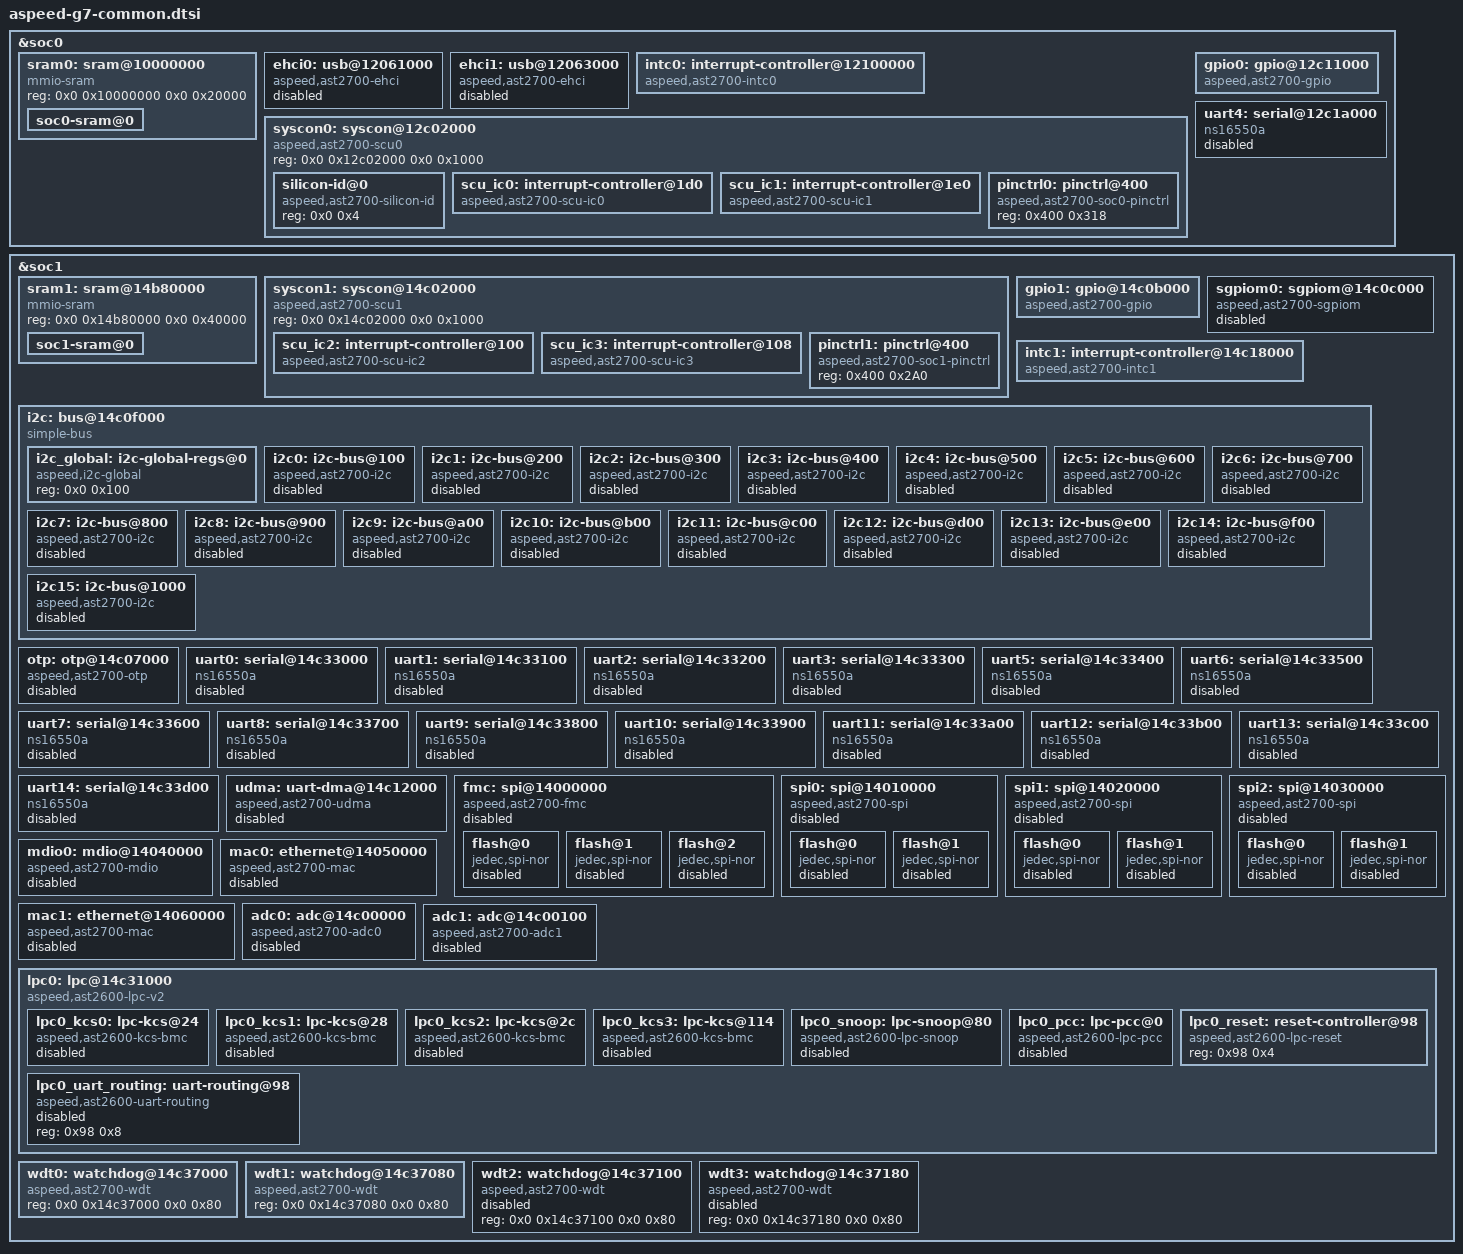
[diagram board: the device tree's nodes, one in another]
// SPDX-License-Identifier: GPL-2.0-only OR MIT
/*
 * Device Tree Source for AST27xx SoC Family Main Domain peripherals
 *
 * Copyright (C) 2026 ASPEED Technology Inc.
 */

#include <dt-bindings/clock/aspeed,ast2700-scu.h>
#include <dt-bindings/reset/aspeed,ast2700-scu.h>
#include <dt-bindings/interrupt-controller/aspeed-scu-ic.h>

&soc0 {
	sram0: sram@10000000 {
		compatible = "mmio-sram";
		reg = <0x0 0x10000000 0x0 0x20000>;
		ranges = <0x0 0x0 0x10000000 0x20000>;
		#address-cells = <1>;
		#size-cells = <1>;

		soc0-sram@0 {
			reg = <0x0 0x20000>;
			export;
		};
	};

	ehci0: usb@12061000 {
		compatible = "aspeed,ast2700-ehci", "generic-ehci";
		reg = <0x0 0x12061000 0x0 0x100>;
		interrupts = <GIC_SPI 33 IRQ_TYPE_LEVEL_HIGH>;
		clocks = <&syscon0 SCU0_CLK_GATE_PORTAUSB2CLK>;
		resets = <&syscon0 SCU0_RESET_PORTA_VHUB_EHCI>;
		pinctrl-names = "default";
		pinctrl-0 = <&pinctrl_usb2ah_default>;
		status = "disabled";
	};

	ehci1: usb@12063000 {
		compatible = "aspeed,ast2700-ehci", "generic-ehci";
		reg = <0x0 0x12063000 0x0 0x100>;
		interrupts = <GIC_SPI 37 IRQ_TYPE_LEVEL_HIGH>;
		clocks = <&syscon0 SCU0_CLK_GATE_PORTBUSB2CLK>;
		resets = <&syscon0 SCU0_RESET_PORTB_VHUB_EHCI>;
		pinctrl-names = "default";
		pinctrl-0 = <&pinctrl_usb2bh_default>;
		status = "disabled";
	};

	intc0: interrupt-controller@12100000 {
		compatible = "aspeed,ast2700-intc0";
		reg = <0x0 0x12100000 0x0 0x3c00>;
		interrupt-controller;
		interrupt-parent = <&gic>;
		#interrupt-cells = <1>;
		aspeed,interrupt-ranges =
			<0 128 &gic GIC_SPI 0 IRQ_TYPE_LEVEL_HIGH>, /* linear range 1 to 1*/
			<144 8 &gic GIC_SPI 144 IRQ_TYPE_LEVEL_HIGH>, /* sw int SSP */
			<152 8 &gic GIC_SPI 152 IRQ_TYPE_LEVEL_HIGH>, /* sw int TSP */
			<192 10 &gic GIC_SPI 192 IRQ_TYPE_LEVEL_HIGH>, /* M0-M9 intm */
			<208 10 &gic GIC_SPI 208 IRQ_TYPE_LEVEL_HIGH>, /* M30-M39 intm */
			<224 10 &gic GIC_SPI 224 IRQ_TYPE_LEVEL_HIGH>, /* M40-M49 intm */
			<256 128 &ssp_nvic 0 0 >, /* linear to SSP */
			<384 10 &ssp_nvic 160 0 >, /* cascaded to SSP via M10-M19 */
			<400 8 &ssp_nvic 144 0 >, /* sw int PSP */
			<408 8 &ssp_nvic 152 0 >, /* sw int TSP */
			<426 128 &tsp_nvic 0 0 >, /* linear to TSP */
			<554 10 &tsp_nvic 160 0 >, /* cascaded to TSP via M20-M29 */
			<570 8 &tsp_nvic 144 0 >, /* sw int PSP */
			<578 8 &tsp_nvic 152 0 >; /* sw int TSP */
	};

	syscon0: syscon@12c02000 {
		compatible = "aspeed,ast2700-scu0", "syscon", "simple-mfd";
		reg = <0x0 0x12c02000 0x0 0x1000>;
		ranges = <0x0 0x0 0x12c02000 0x1000>;
		#address-cells = <1>;
		#size-cells = <1>;
		#clock-cells = <1>;
		#reset-cells = <1>;

		silicon-id@0 {
			compatible = "aspeed,ast2700-silicon-id", "aspeed,silicon-id";
			reg = <0x0 0x4>;
		};

		scu_ic0: interrupt-controller@1d0 {
			compatible = "aspeed,ast2700-scu-ic0";
			reg = <0x1d0 0xc>;
			interrupts-extended = <&intc0 97>;
			#interrupt-cells = <1>;
			interrupt-controller;
		};

		scu_ic1: interrupt-controller@1e0 {
			compatible = "aspeed,ast2700-scu-ic1";
			reg = <0x1e0 0xc>;
			interrupts-extended = <&intc0 98>;
			#interrupt-cells = <1>;
			interrupt-controller;
		};

		pinctrl0: pinctrl@400 {
			compatible = "aspeed,ast2700-soc0-pinctrl";
			reg = <0x400 0x318>;
		};
	};

	gpio0: gpio@12c11000 {
		#gpio-cells = <2>;
		gpio-controller;
		compatible = "aspeed,ast2700-gpio";
		reg = <0x0 0x12c11000 0x0 0x1000>;
		interrupts-extended = <&intc0 11>;
		gpio-ranges = <&pinctrl0 0 0 12>;
		ngpios = <12>;
		clocks = <&syscon0 SCU0_CLK_APB>;
		interrupt-controller;
		#interrupt-cells = <2>;
	};

	uart4: serial@12c1a000 {
		compatible = "ns16550a";
		reg = <0x0 0x12c1a000 0x0 0x1000>;
		reg-shift = <2>;
		reg-io-width = <4>;
		clocks = <&syscon0 SCU0_CLK_GATE_UART4CLK>;
		interrupts-extended = <&intc0 8>;
		no-loopback-test;
		status = "disabled";
	};
};

&soc1 {
	sram1: sram@14b80000 {
		compatible = "mmio-sram";
		reg = <0x0 0x14b80000 0x0 0x40000>;
		ranges = <0x0 0x0 0x14b80000 0x40000>;
		#address-cells = <1>;
		#size-cells = <1>;

		soc1-sram@0 {
			reg = <0x0 0x40000>;
			export;
		};
	};

	syscon1: syscon@14c02000 {
		compatible = "aspeed,ast2700-scu1", "syscon", "simple-mfd";
		reg = <0x0 0x14c02000 0x0 0x1000>;
		ranges = <0x0 0x0 0x14c02000 0x1000>;
		#address-cells = <1>;
		#size-cells = <1>;
		#clock-cells = <1>;
		#reset-cells = <1>;

		scu_ic2: interrupt-controller@100 {
			compatible = "aspeed,ast2700-scu-ic2";
			reg = <0x100 0x8>;
			interrupts-extended = <&intc1 160>;
			#interrupt-cells = <1>;
			interrupt-controller;
		};

		scu_ic3: interrupt-controller@108 {
			compatible = "aspeed,ast2700-scu-ic3";
			reg = <0x108 0x8>;
			interrupts-extended = <&intc1 186>;
			#interrupt-cells = <1>;
			interrupt-controller;
		};

		pinctrl1: pinctrl@400 {
			compatible = "aspeed,ast2700-soc1-pinctrl";
			reg = <0x400 0x2A0>;
		};
	};

	gpio1: gpio@14c0b000 {
		#gpio-cells = <2>;
		gpio-controller;
		compatible = "aspeed,ast2700-gpio";
		reg = <0x0 0x14c0b000 0x0 0x1000>;
		interrupts-extended = <&intc1 82>;
		gpio-ranges = <&pinctrl1 0 0 216>;
		ngpios = <216>;
		clocks = <&syscon1 SCU1_CLK_AHB>;
		interrupt-controller;
		#interrupt-cells = <2>;
	};

	sgpiom0: sgpiom@14c0c000 {
		#gpio-cells = <2>;
		gpio-controller;
		compatible = "aspeed,ast2700-sgpiom";
		reg = <0x0 0x14c0c000 0x0 0x100>;
		interrupts-extended = <&intc1 85>;
		clocks = <&syscon1 SCU1_CLK_APB>;
		interrupt-controller;
		#interrupt-cells = <2>;
		ngpios = <256>;
		bus-frequency = <12000000>;
		pinctrl-names = "default";
		pinctrl-0 = <&pinctrl_sgpm0_default>;
		status = "disabled";
	};

	intc1: interrupt-controller@14c18000 {
		compatible = "aspeed,ast2700-intc1";
		reg = <0 0x14c18000 0 0x400>;
		interrupt-controller;
		interrupt-parent = <&intc0>;
		#interrupt-cells = <1>;
		aspeed,interrupt-ranges =
			<0 6 &intc0 480>,   /* M0  ~ M5  */
			<10 6 &intc0 490>,   /* M10 ~ M15  */
			<20 6 &intc0 500>,   /* M20 ~ M15  */
			<30 6 &intc0 510>,   /* M30 ~ M15  */
			<40 6 &intc0 520>,   /* M40 ~ M15  */
			<50 1 &bootmcu_intc 0>; /* only 1 pin to BootMCU */
	};

	i2c: bus@14c0f000 {
		compatible = "simple-bus";
		#address-cells = <1>;
		#size-cells = <1>;
		ranges = <0x0 0x0 0x14c0f000 0x1100>;
	};

	otp: otp@14c07000 {
		compatible = "aspeed,ast2700-otp";
		reg = <0 0x14c07000 0 0x1000>;
		interrupts-extended = <&intc1 168>;
		aspeed,scu0 = <&syscon0>;
		aspeed,scu1 = <&syscon1>;
		status = "disabled";
	};

	uart0: serial@14c33000 {
		compatible = "ns16550a";
		reg = <0x0 0x14c33000 0x0 0x100>;
		reg-shift = <2>;
		reg-io-width = <4>;
		clocks = <&syscon1 SCU1_CLK_GATE_UART0CLK>;
		interrupts-extended = <&intc1 135>;
		no-loopback-test;
		status = "disabled";
	};

	uart1: serial@14c33100 {
		compatible = "ns16550a";
		reg = <0x0 0x14c33100 0x0 0x100>;
		reg-shift = <2>;
		reg-io-width = <4>;
		clocks = <&syscon1 SCU1_CLK_GATE_UART1CLK>;
		interrupts-extended = <&intc1 136>;
		no-loopback-test;
		status = "disabled";
	};

	uart2: serial@14c33200 {
		compatible = "ns16550a";
		reg = <0x0 0x14c33200 0x0 0x100>;
		reg-shift = <2>;
		reg-io-width = <4>;
		clocks = <&syscon1 SCU1_CLK_GATE_UART2CLK>;
		interrupts-extended = <&intc1 137>;
		no-loopback-test;
		status = "disabled";
	};

	uart3: serial@14c33300 {
		compatible = "ns16550a";
		reg = <0x0 0x14c33300 0x0 0x100>;
		reg-shift = <2>;
		reg-io-width = <4>;
		clocks = <&syscon1 SCU1_CLK_GATE_UART3CLK>;
		interrupts-extended = <&intc1 138>;
		no-loopback-test;
		status = "disabled";
	};

	uart5: serial@14c33400 {
		compatible = "ns16550a";
		reg = <0x0 0x14c33400 0x0 0x100>;
		reg-shift = <2>;
		reg-io-width = <4>;
		clocks = <&syscon1 SCU1_CLK_GATE_UART5CLK>;
		interrupts-extended = <&intc1 139>;
		no-loopback-test;
		status = "disabled";
	};

	uart6: serial@14c33500 {
		compatible = "ns16550a";
		reg = <0x0 0x14c33500 0x0 0x100>;
		reg-shift = <2>;
		reg-io-width = <4>;
		clocks = <&syscon1 SCU1_CLK_GATE_UART6CLK>;
		interrupts-extended = <&intc1 140>;
		no-loopback-test;
		status = "disabled";
	};

	uart7: serial@14c33600 {
		compatible = "ns16550a";
		reg = <0x0 0x14c33600 0x0 0x100>;
		reg-shift = <2>;
		reg-io-width = <4>;
		clocks = <&syscon1 SCU1_CLK_GATE_UART7CLK>;
		interrupts-extended = <&intc1 141>;
		no-loopback-test;
		status = "disabled";
	};

	uart8: serial@14c33700 {
		compatible = "ns16550a";
		reg = <0x0 0x14c33700 0x0 0x100>;
		reg-shift = <2>;
		reg-io-width = <4>;
		clocks = <&syscon1 SCU1_CLK_GATE_UART8CLK>;
		interrupts-extended = <&intc1 142>;
		no-loopback-test;
		status = "disabled";
	};

	uart9: serial@14c33800 {
		compatible = "ns16550a";
		reg = <0x0 0x14c33800 0x0 0x100>;
		reg-shift = <2>;
		reg-io-width = <4>;
		clocks = <&syscon1 SCU1_CLK_GATE_UART9CLK>;
		interrupts-extended = <&intc1 143>;
		no-loopback-test;
		status = "disabled";
	};

	uart10: serial@14c33900 {
		compatible = "ns16550a";
		reg = <0x0 0x14c33900 0x0 0x100>;
		reg-shift = <2>;
		reg-io-width = <4>;
		clocks = <&syscon1 SCU1_CLK_GATE_UART10CLK>;
		interrupts-extended = <&intc1 144>;
		no-loopback-test;
		status = "disabled";
	};

	uart11: serial@14c33a00 {
		compatible = "ns16550a";
		reg = <0x0 0x14c33a00 0x0 0x100>;
		reg-shift = <2>;
		reg-io-width = <4>;
		clocks = <&syscon1 SCU1_CLK_GATE_UART11CLK>;
		interrupts-extended = <&intc1 145>;
		no-loopback-test;
		status = "disabled";
	};

	uart12: serial@14c33b00 {
		compatible = "ns16550a";
		reg = <0x0 0x14c33b00 0x0 0x100>;
		reg-shift = <2>;
		reg-io-width = <4>;
		clocks = <&syscon1 SCU1_CLK_GATE_UART12CLK>;
		interrupts-extended = <&intc1 146>;
		no-loopback-test;
		status = "disabled";
	};

	uart13: serial@14c33c00 {
		compatible = "ns16550a";
		reg = <0x0 0x14c33c00 0x0 0x100>;
		reg-shift = <2>;
		reg-io-width = <4>;
		clocks = <&syscon1 SCU1_CLK_UART13>;
		interrupts-extended = <&intc1 23>;
		no-loopback-test;
		status = "disabled";
	};

	uart14: serial@14c33d00 {
		compatible = "ns16550a";
		reg = <0x0 0x14c33d00 0x0 0x100>;
		reg-shift = <2>;
		reg-io-width = <4>;
		clocks = <&syscon1 SCU1_CLK_UART14>;
		interrupts-extended = <&intc1 55>;
		no-loopback-test;
		status = "disabled";
	};

	udma: uart-dma@14c12000 {
		compatible = "aspeed,ast2700-udma";
		reg = <0x0 0x14c12000 0x0 0x1000>;
		interrupts-extended = <&intc1 147>;
		dma-channels = <32>;
		#dma-cells = <1>;
		status = "disabled";
	};

	fmc: spi@14000000 {
		reg = <0x0 0x14000000 0x0 0xc4>, <0x1 0x00000000 0x0 0x80000000>;
		#address-cells = <1>;
		#size-cells = <0>;
		compatible = "aspeed,ast2700-fmc";
		clocks = <&syscon1 SCU1_CLK_AHB>;
		interrupts-extended = <&intc1 121>;
		status = "disabled";
		num-cs = <3>;

		flash@0 {
			reg = < 0 >;
			compatible = "jedec,spi-nor";
			spi-max-frequency = <50000000>;
			spi-rx-bus-width = <2>;
			status = "disabled";
		};

		flash@1 {
			reg = < 1 >;
			compatible = "jedec,spi-nor";
			spi-max-frequency = <50000000>;
			spi-rx-bus-width = <2>;
			status = "disabled";
		};

		flash@2 {
			reg = < 2 >;
			compatible = "jedec,spi-nor";
			spi-max-frequency = <50000000>;
			spi-rx-bus-width = <2>;
			status = "disabled";
		};
	};

	spi0: spi@14010000 {
		reg = <0x0 0x14010000 0x0 0xc4>, <0x1 0x80000000 0x0 0x80000000>;
		#address-cells = <1>;
		#size-cells = <0>;
		compatible = "aspeed,ast2700-spi";
		clocks = <&syscon1 SCU1_CLK_AHB>;
		interrupts-extended = <&intc1 122>;
		status = "disabled";
		num-cs = <2>;

		flash@0 {
			reg = < 0 >;
			compatible = "jedec,spi-nor";
			spi-max-frequency = <50000000>;
			spi-rx-bus-width = <2>;
			status = "disabled";
		};

		flash@1 {
			reg = < 1 >;
			compatible = "jedec,spi-nor";
			spi-max-frequency = <50000000>;
			spi-rx-bus-width = <2>;
			status = "disabled";
		};
	};

	spi1: spi@14020000 {
		reg = <0x0 0x14020000 0x0 0xc4>, <0x2 0x00000000 0x0 0x80000000>;
		#address-cells = <1>;
		#size-cells = <0>;
		compatible = "aspeed,ast2700-spi";
		clocks = <&syscon1 SCU1_CLK_AHB>;
		interrupts-extended = <&intc1 123>;
		status = "disabled";
		num-cs = <2>;

		flash@0 {
			reg = < 0 >;
			compatible = "jedec,spi-nor";
			spi-max-frequency = <50000000>;
			spi-rx-bus-width = <2>;
			status = "disabled";
		};

		flash@1 {
			reg = < 1 >;
			compatible = "jedec,spi-nor";
			spi-max-frequency = <50000000>;
			spi-rx-bus-width = <2>;
			status = "disabled";
		};
	};

	spi2: spi@14030000 {
		reg = <0x0 0x14030000 0x0 0x1f0>, <0x2 0x80000000 0x0 0x80000000>;
		#address-cells = <1>;
		#size-cells = <0>;
		compatible = "aspeed,ast2700-spi";
		clocks = <&syscon1 SCU1_CLK_AHB>;
		interrupts-extended = <&intc1 124>;
		status = "disabled";
		num-cs = <2>;

		flash@0 {
			reg = < 0 >;
			compatible = "jedec,spi-nor";
			spi-max-frequency = <50000000>;
			spi-rx-bus-width = <2>;
			status = "disabled";
		};

		flash@1 {
			reg = < 1 >;
			compatible = "jedec,spi-nor";
			spi-max-frequency = <50000000>;
			spi-rx-bus-width = <2>;
			status = "disabled";
		};
	};

	mdio0: mdio@14040000 {
		compatible = "aspeed,ast2700-mdio", "aspeed,ast2600-mdio";
		reg = <0x0 0x14040000 0x0 0x8>;
		resets = <&syscon1 SCU1_RESET_MII>;
		pinctrl-names = "default";
		pinctrl-0 = <&pinctrl_mdio0_default>;
		#address-cells = <1>;
		#size-cells = <0>;
		status = "disabled";
	};

	mac0: ethernet@14050000 {
		compatible = "aspeed,ast2700-mac", "faraday,ftgmac100";
		reg = <0x0 0x14050000 0x0 0x200>;
		interrupts-extended = <&intc1 128>;
		clocks = <&syscon1 SCU1_CLK_GATE_MAC0CLK>;
		resets = <&syscon1 SCU1_RESET_MAC0>;
		aspeed,scu = <&syscon1>;
		status = "disabled";
	};

	mac1: ethernet@14060000 {
		compatible = "aspeed,ast2700-mac", "faraday,ftgmac100";
		reg = <0x0 0x14060000 0x0 0x200>;
		interrupts-extended = <&intc1 129>;
		clocks = <&syscon1 SCU1_CLK_GATE_MAC1CLK>;
		resets = <&syscon1 SCU1_RESET_MAC1>;
		aspeed,scu = <&syscon1>;
		status = "disabled";
	};

	adc0: adc@14c00000 {
		compatible = "aspeed,ast2700-adc0";
		reg = <0x0 0x14c00000 0 0x100>;
		clocks = <&syscon1 SCU1_CLK_AHB>;
		resets = <&syscon1 SCU1_RESET_ADC>;
		interrupts-extended = <&intc1 80>;
		#io-channel-cells = <1>;
		aspeed,scu = <&syscon1>;
		status = "disabled";
	};

	adc1: adc@14c00100 {
		compatible = "aspeed,ast2700-adc1";
		reg = <0x0 0x14c00100 0x0 0x100>;
		clocks = <&syscon1 SCU1_CLK_AHB>;
		resets = <&syscon1 SCU1_RESET_ADC>;
		interrupts-extended = <&intc1 80>;
		#io-channel-cells = <1>;
		aspeed,scu = <&syscon1>;
		status = "disabled";
	};

	lpc0: lpc@14c31000 {
		compatible = "aspeed,ast2600-lpc-v2", "simple-mfd", "syscon";
		reg = <0x0 0x14c31000 0x0 0x1000>;
		reg-io-width = <4>;

		#address-cells = <1>;
		#size-cells = <1>;
		ranges = <0x0 0x0 0x14c31000 0x1000>;

		lpc0_kcs0: lpc-kcs@24 {
			compatible = "aspeed,ast2600-kcs-bmc";
			reg = <0x24 0x1>, <0x30 0x1>, <0x3c 0x1>;
			interrupts-extended = <&intc1 4>;
			status = "disabled";
		};

		lpc0_kcs1: lpc-kcs@28 {
			compatible = "aspeed,ast2600-kcs-bmc";
			reg = <0x28 0x1>, <0x34 0x1>, <0x40 0x1>;
			interrupts-extended = <&intc1 5>;
			status = "disabled";
		};

		lpc0_kcs2: lpc-kcs@2c {
			compatible = "aspeed,ast2600-kcs-bmc";
			reg = <0x2c 0x1>, <0x38 0x1>, <0x44 0x1>;
			interrupts-extended = <&intc1 6>;
			status = "disabled";
		};

		lpc0_kcs3: lpc-kcs@114 {
			compatible = "aspeed,ast2600-kcs-bmc";
			reg = <0x114 0x1>, <0x118 0x1>, <0x11c 0x1>;
			interrupts-extended = <&intc1 7>;
			status = "disabled";
		};

		lpc0_snoop: lpc-snoop@80 {
			compatible = "aspeed,ast2600-lpc-snoop";
			reg = <0x80 0x80>;
			interrupts-extended = <&intc1 1>;
			status = "disabled";
		};

		lpc0_pcc: lpc-pcc@0 {
			compatible = "aspeed,ast2600-lpc-pcc";
			reg = <0x0 0x140>;
			interrupts-extended = <&intc1 3>;
			status = "disabled";
		};

		lpc0_reset: reset-controller@98 {
			compatible = "aspeed,ast2600-lpc-reset";
			reg = <0x98 0x4>;
			#reset-cells = <1>;
		};

		lpc0_uart_routing: uart-routing@98 {
			compatible = "aspeed,ast2600-uart-routing";
			reg = <0x98 0x8>;
			status = "disabled";
		};
	};

	wdt0: watchdog@14c37000 {
		compatible = "aspeed,ast2700-wdt";
		reg = <0x0 0x14c37000 0x0 0x80>;
	};

	wdt1: watchdog@14c37080 {
		compatible = "aspeed,ast2700-wdt";
		reg = <0x0 0x14c37080 0x0 0x80>;
	};

	wdt2: watchdog@14c37100 {
		compatible = "aspeed,ast2700-wdt";
		reg = <0x0 0x14c37100 0x0 0x80>;
		status = "disabled";
	};

	wdt3: watchdog@14c37180 {
		compatible = "aspeed,ast2700-wdt";
		reg = <0x0 0x14c37180 0x0 0x80>;
		status = "disabled";
	};
};

#include "aspeed-g7-pinctrl.dtsi"

&i2c {
	i2c_global: i2c-global-regs@0 {
		compatible = "aspeed,i2c-global", "simple-mfd", "syscon";
		reg = <0x0 0x100>;
	};

	i2c0: i2c-bus@100 {
		#address-cells = <1>;
		#size-cells = <0>;
		reg = <0x100 0xA0>, <0x1C0 0x40>;
		compatible = "aspeed,ast2700-i2c";
		aspeed,global-regs = <&i2c_global>;
		aspeed,enable-dma;
		clocks = <&syscon1 SCU1_CLK_APB>;
		resets = <&syscon1 SCU1_RESET_I2C>;
		interrupts-extended = <&intc1 64>;
		clock-frequency = <100000>;
		debounce-level = <2>;
		pinctrl-names = "default";
		pinctrl-0 = <&pinctrl_i2c0_default>;
		status = "disabled";
	};

	i2c1: i2c-bus@200 {
		#address-cells = <1>;
		#size-cells = <0>;
		reg = <0x200 0xA0>, <0x2C0 0x40>;
		compatible = "aspeed,ast2700-i2c";
		aspeed,global-regs = <&i2c_global>;
		aspeed,enable-dma;
		clocks = <&syscon1 SCU1_CLK_APB>;
		resets = <&syscon1 SCU1_RESET_I2C>;
		interrupts-extended = <&intc1 65>;
		clock-frequency = <100000>;
		debounce-level = <2>;
		pinctrl-names = "default";
		pinctrl-0 = <&pinctrl_i2c1_default>;
		status = "disabled";
	};

	i2c2: i2c-bus@300 {
		#address-cells = <1>;
		#size-cells = <0>;
		reg = <0x300 0xA0>, <0x3C0 0x40>;
		compatible = "aspeed,ast2700-i2c";
		aspeed,global-regs = <&i2c_global>;
		aspeed,enable-dma;
		clocks = <&syscon1 SCU1_CLK_APB>;
		resets = <&syscon1 SCU1_RESET_I2C>;
		interrupts-extended = <&intc1 66>;
		clock-frequency = <100000>;
		debounce-level = <2>;
		pinctrl-names = "default";
		pinctrl-0 = <&pinctrl_i2c2_default>;
		status = "disabled";
	};

	i2c3: i2c-bus@400 {
		#address-cells = <1>;
		#size-cells = <0>;
		reg = <0x400 0xA0>, <0x4C0 0x40>;
		compatible = "aspeed,ast2700-i2c";
		aspeed,global-regs = <&i2c_global>;
		aspeed,enable-dma;
		clocks = <&syscon1 SCU1_CLK_APB>;
		resets = <&syscon1 SCU1_RESET_I2C>;
		interrupts-extended = <&intc1 67>;
		clock-frequency = <100000>;
		debounce-level = <2>;
		pinctrl-names = "default";
		pinctrl-0 = <&pinctrl_i2c3_default>;
		status = "disabled";
	};

	i2c4: i2c-bus@500 {
		#address-cells = <1>;
		#size-cells = <0>;
		reg = <0x500 0xA0>, <0x5C0 0x40>;
		compatible = "aspeed,ast2700-i2c";
		aspeed,global-regs = <&i2c_global>;
		aspeed,enable-dma;
		clocks = <&syscon1 SCU1_CLK_APB>;
		resets = <&syscon1 SCU1_RESET_I2C>;
		interrupts-extended = <&intc1 68>;
		clock-frequency = <100000>;
		debounce-level = <2>;
		pinctrl-names = "default";
		pinctrl-0 = <&pinctrl_i2c4_default>;
		status = "disabled";
	};

	i2c5: i2c-bus@600 {
		#address-cells = <1>;
		#size-cells = <0>;
		reg = <0x600 0xA0>, <0x6C0 0x40>;
		compatible = "aspeed,ast2700-i2c";
		aspeed,global-regs = <&i2c_global>;
		aspeed,enable-dma;
		clocks = <&syscon1 SCU1_CLK_APB>;
		resets = <&syscon1 SCU1_RESET_I2C>;
		interrupts-extended = <&intc1 69>;
		clock-frequency = <100000>;
		debounce-level = <2>;
		pinctrl-names = "default";
		pinctrl-0 = <&pinctrl_i2c5_default>;
		status = "disabled";
	};

	i2c6: i2c-bus@700 {
		#address-cells = <1>;
		#size-cells = <0>;
		reg = <0x700 0xA0>, <0x7C0 0x40>;
		compatible = "aspeed,ast2700-i2c";
		aspeed,global-regs = <&i2c_global>;
		aspeed,enable-dma;
		clocks = <&syscon1 SCU1_CLK_APB>;
		resets = <&syscon1 SCU1_RESET_I2C>;
		interrupts-extended = <&intc1 70>;
		clock-frequency = <100000>;
		debounce-level = <2>;
		pinctrl-names = "default";
		pinctrl-0 = <&pinctrl_i2c6_default>;
		status = "disabled";
	};

	i2c7: i2c-bus@800 {
		#address-cells = <1>;
		#size-cells = <0>;
		reg = <0x800 0xA0>, <0x8C0 0x40>;
		compatible = "aspeed,ast2700-i2c";
		aspeed,global-regs = <&i2c_global>;
		aspeed,enable-dma;
		clocks = <&syscon1 SCU1_CLK_APB>;
		resets = <&syscon1 SCU1_RESET_I2C>;
		interrupts-extended = <&intc1 71>;
		clock-frequency = <100000>;
		debounce-level = <2>;
		pinctrl-names = "default";
		pinctrl-0 = <&pinctrl_i2c7_default>;
		status = "disabled";
	};

	i2c8: i2c-bus@900 {
		#address-cells = <1>;
		#size-cells = <0>;
		reg = <0x900 0xA0>, <0x9C0 0x40>;
		compatible = "aspeed,ast2700-i2c";
		aspeed,global-regs = <&i2c_global>;
		aspeed,enable-dma;
		clocks = <&syscon1 SCU1_CLK_APB>;
		resets = <&syscon1 SCU1_RESET_I2C>;
		interrupts-extended = <&intc1 72>;
		clock-frequency = <100000>;
		debounce-level = <2>;
		pinctrl-names = "default";
		pinctrl-0 = <&pinctrl_i2c8_default>;
		status = "disabled";
	};

	i2c9: i2c-bus@a00 {
		#address-cells = <1>;
		#size-cells = <0>;
		reg = <0xA00 0xA0>, <0xAC0 0x40>;
		compatible = "aspeed,ast2700-i2c";
		aspeed,global-regs = <&i2c_global>;
		aspeed,enable-dma;
		clocks = <&syscon1 SCU1_CLK_APB>;
		resets = <&syscon1 SCU1_RESET_I2C>;
		interrupts-extended = <&intc1 73>;
		clock-frequency = <100000>;
		debounce-level = <2>;
		pinctrl-names = "default";
		pinctrl-0 = <&pinctrl_i2c9_default>;
		status = "disabled";
	};

	i2c10: i2c-bus@b00 {
		#address-cells = <1>;
		#size-cells = <0>;
		reg = <0xB00 0xA0>, <0xBC0 0x40>;
		compatible = "aspeed,ast2700-i2c";
		aspeed,global-regs = <&i2c_global>;
		aspeed,enable-dma;
		clocks = <&syscon1 SCU1_CLK_APB>;
		resets = <&syscon1 SCU1_RESET_I2C>;
		interrupts-extended = <&intc1 74>;
		clock-frequency = <100000>;
		debounce-level = <2>;
		pinctrl-names = "default";
		pinctrl-0 = <&pinctrl_i2c10_default>;
		status = "disabled";
	};

	i2c11: i2c-bus@c00 {
		#address-cells = <1>;
		#size-cells = <0>;
		reg = <0xC00 0xA0>, <0xCC0 0x40>;
		compatible = "aspeed,ast2700-i2c";
		aspeed,global-regs = <&i2c_global>;
		aspeed,enable-dma;
		clocks = <&syscon1 SCU1_CLK_APB>;
		resets = <&syscon1 SCU1_RESET_I2C>;
		interrupts-extended = <&intc1 75>;
		clock-frequency = <100000>;
		debounce-level = <2>;
		pinctrl-names = "default";
		pinctrl-0 = <&pinctrl_i2c11_default>;
		status = "disabled";
	};

	i2c12: i2c-bus@d00 {
		#address-cells = <1>;
		#size-cells = <0>;
		reg = <0xD00 0xA0>, <0xDC0 0x40>;
		compatible = "aspeed,ast2700-i2c";
		aspeed,global-regs = <&i2c_global>;
		aspeed,enable-dma;
		clocks = <&syscon1 SCU1_CLK_APB>;
		resets = <&syscon1 SCU1_RESET_I2C>;
		interrupts-extended = <&intc1 76>;
		clock-frequency = <100000>;
		debounce-level = <2>;
		pinctrl-names = "default";
		pinctrl-0 = <&pinctrl_i2c12_default>;
		status = "disabled";
	};

	i2c13: i2c-bus@e00 {
		#address-cells = <1>;
		#size-cells = <0>;
		reg = <0xE00 0xA0>, <0xEC0 0x40>;
		compatible = "aspeed,ast2700-i2c";
		aspeed,global-regs = <&i2c_global>;
		aspeed,enable-dma;
		clocks = <&syscon1 SCU1_CLK_APB>;
		resets = <&syscon1 SCU1_RESET_I2C>;
		interrupts-extended = <&intc1 77>;
		clock-frequency = <100000>;
		debounce-level = <2>;
		pinctrl-names = "default";
		pinctrl-0 = <&pinctrl_i2c13_default>;
		status = "disabled";
	};

	i2c14: i2c-bus@f00 {
		#address-cells = <1>;
		#size-cells = <0>;
		reg = <0xF00 0xA0>, <0xFC0 0x40>;
		compatible = "aspeed,ast2700-i2c";
		aspeed,global-regs = <&i2c_global>;
		aspeed,enable-dma;
		clocks = <&syscon1 SCU1_CLK_APB>;
		resets = <&syscon1 SCU1_RESET_I2C>;
		interrupts-extended = <&intc1 78>;
		clock-frequency = <100000>;
		debounce-level = <2>;
		pinctrl-names = "default";
		pinctrl-0 = <&pinctrl_i2c14_default>;
		status = "disabled";
	};

	i2c15: i2c-bus@1000 {
		#address-cells = <1>;
		#size-cells = <0>;
		reg = <0x1000 0xA0>, <0x10C0 0x40>;
		compatible = "aspeed,ast2700-i2c";
		aspeed,global-regs = <&i2c_global>;
		aspeed,enable-dma;
		clocks = <&syscon1 SCU1_CLK_APB>;
		resets = <&syscon1 SCU1_RESET_I2C>;
		interrupts-extended = <&intc1 79>;
		clock-frequency = <100000>;
		debounce-level = <2>;
		pinctrl-names = "default";
		pinctrl-0 = <&pinctrl_i2c15_default>;
		status = "disabled";
	};
};
